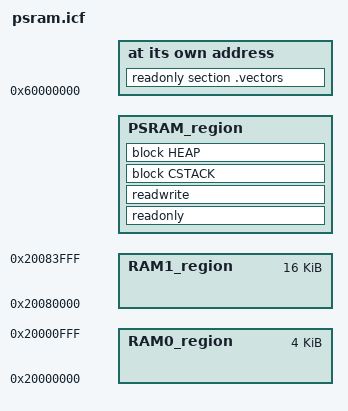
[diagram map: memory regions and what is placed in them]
/*###ICF### Section handled by ICF editor, don't touch! ****/
/*-Editor annotation file-*/
/* IcfEditorFile="$TOOLKIT_DIR$\config\ide\IcfEditor\a_v1_0.xml" */
/*-Vector table start*/
define symbol __ICFEDIT_vector_start__ = 0x60000000;    /*Add for CMSIS*/
/*-Memory Regions-*/
define symbol __ICFEDIT_region_RAM0_start__   = 0x20000000;
define symbol __ICFEDIT_region_RAM0_end__     = 0x20000FFF;
define symbol __ICFEDIT_region_RAM1_start__   = 0x20080000;
define symbol __ICFEDIT_region_RAM1_end__     = 0x20083FFF;
define symbol __ICFEDIT_region_PSRAM_start__  = 0x60000000;
define symbol __ICFEDIT_region_PSRAM_end__    = 0x600FFFFF;
/*-Sizes-*/
if (!isdefinedsymbol(__ICFEDIT_size_cstack__)) {
define symbol __ICFEDIT_size_cstack__        = 0x400;
}
if (!isdefinedsymbol(__ICFEDIT_size_heap__)) {
define symbol __ICFEDIT_size_heap__          = 0x200;
}
/*-Specials-*/
/*define symbol __ICFEDIT_region_RAM_VECT_start__ = __ICFEDIT_region_RAM0_start__;*/ /*Referenced for CMSIS*/
/*define symbol __ICFEDIT_size_vectors__          = 0x100;*/ /*Referenced for CMSIS*/
/*-Exports-*/
export symbol __ICFEDIT_region_RAM_VECT_start__; /*Add for CMSIS*/
/**** End of ICF editor section. ###ICF###*/

define memory mem with size   = 4G;
/*define region RAM_VECT_region = mem:[from __ICFEDIT_region_RAM_VECT_start__ size __ICFEDIT_size_vectors__];*/
/*define region RAM0_region     = mem:[from __ICFEDIT_region_RAM0_start__+__ICFEDIT_size_vectors__ to __ICFEDIT_region_RAM0_end__];*/ /*Referenced for CMSIS*/
define region RAM0_region     = mem:[from __ICFEDIT_region_RAM0_start__ to __ICFEDIT_region_RAM0_end__];
define region RAM1_region     = mem:[from __ICFEDIT_region_RAM1_start__ to __ICFEDIT_region_RAM1_end__];
/*define region RAM_region      = mem:[from __ICFEDIT_region_RAM0_start__+__ICFEDIT_size_vectors__ to __ICFEDIT_region_RAM0_end__] |
                                mem:[from __ICFEDIT_region_RAM1_start__ to __ICFEDIT_region_RAM1_end__];*/ /*Referenced for CMSIS*/
define region PSRAM_region    = mem:[from __ICFEDIT_region_PSRAM_start__ to __ICFEDIT_region_RSRAM_end__];

/*define block RamVect   with alignment = 8, size = __ICFEDIT_size_vectors__  { };*/ /*Referenced for CMSIS*/
define block CSTACK    with alignment = 8, size = __ICFEDIT_size_cstack__   { };
define block HEAP      with alignment = 8, size = __ICFEDIT_size_heap__     { };

initialize by copy { readwrite };
do not initialize  { section .noinit };

/*place at start of PSRAM_region { readonly section .vectors };*/ /*Referenced for CMSIS*/
place at address mem:__ICFEDIT_vector_start__ { readonly section .vectors }; /*Add for CMSIS*/
place in PSRAM_region          { readonly };
place in PSRAM_region          { readwrite, block CSTACK, block HEAP };
/*place in RAM_VECT_region       { block RamVect };*/ /*Referenced for CMSIS*/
